AUTOSAR XML (schema 4-3-0)
package /PEPS/ComponentTypes_PEPS
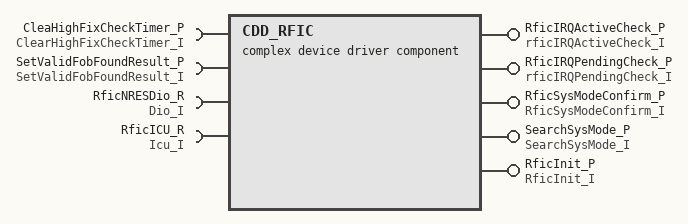
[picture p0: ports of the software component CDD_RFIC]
  complex device driver sw component type CDD_RFIC
    4 x provide port:
      RficIRQActiveCheck_P: server-com-spec{operation=CS, queue-length=1}, provided-interface=rficIRQActiveCheck_I
      RficIRQPendingCheck_P: server-com-spec{operation=CS, queue-length=1}, provided-interface=rficIRQPendingCheck_I
      RficSysModeConfirm_P: nonqueued-sender-com-spec{data-element=SR_RficSysModeConfirm, init-value=0}, provided-interface=RficSysModeConfirm_I
      SearchSysMode_P: server-com-spec{operation=CS, queue-length=1}, provided-interface=SearchSysMode_I
    4 x require port:
      CleaHighFixCheckTimer_P: client-com-spec=CS, required-interface=ClearHighFixCheckTimer_I
      SetValidFobFoundResult_P: client-com-spec=CS, required-interface=SetValidFobFoundResult_I
      RficNRESDio_R: required-com-specs=[Write, Read], required-interface=Dio_I
      RficICU_R: required-com-specs=[IcuDisableNotification, IcuDisableEdgeDetection, IcuEnableEdgeDetection, IcuEnableNotification], required-interface=Icu_I
    provide port RficInit_P: server-com-spec{operation=CS, queue-length=1}, provided-interface=RficInit_I
    behavior CDD_RFIC_InternalBehavior
      4 x operation invoked event:
        OIE_RE_rfic_IRQ_ActiveCheck_RficIRQActiveCheck_P_CS: start-on-event=RE_rfic_IRQ_ActiveCheck, operation=RficIRQActiveCheck_P.CS
        OIE_RE_rfic_IRQ_PendingCheck_RficIRQPendingCheck_P_CS: start-on-event=RE_rfic_IRQ_PendingCheck, operation=RficIRQPendingCheck_P.CS
        OIE_RE_SearchSysmode_SearchSysMode_P_CS: start-on-event=RE_SearchSysmode, operation=SearchSysMode_P.CS
        OIT_RE_rfic_init_RficInit_P_CS: start-on-event=RE_rfic_init, operation=RficInit_P.CS
      6 x runnable:
        RE_RFIC_Control_ISR
          data-send-points:
            access DSP_RE_RFIC_Control_ISR_RficSysModeConfirm_P_SR: accessed-variable=RficSysModeConfirm_P.SR_RficSysModeConfirm
          sync call SSCP_RE_RFIC_Control_ISR_SetValidFobFoundResult_P_CS: operation=SetValidFobFoundResult_P.CS
        RE_rfic_init
          async call AC_RficNRESDio_R_Read: operation=RficNRESDio_R.Read
          5 x sync call:
            SC_RficNRESDio_R_Write: operation=RficNRESDio_R.Write
            SC_RficICU_P_IcuDisableEdgeDetection: operation=RficICU_R.IcuDisableEdgeDetection
            SC_RficICU_P_IcuDisableNotification: operation=RficICU_R.IcuDisableNotification
            SC_RficICU_P_IcuEnableEdgeDetection: operation=RficICU_R.IcuEnableEdgeDetection
            SC_RficICU_P_IcuEnableNotification: operation=RficICU_R.IcuEnableNotification
        RE_rfic_IRQ_ActiveCheck
        RE_rfic_IRQ_PendingCheck
        RE_RFIC_WakeUp
          sync call SSCP_RE_RFIC_WakeUp_ClearHighFixCheckTimer_P_CS: operation=CleaHighFixCheckTimer_P.CS
        RE_SearchSysmode
  swc implementation CDD_RFIC_Implementation: behavior=CDD_RFIC_InternalBehavior
    code-descriptors:
      code Default: artifact-descriptors=autosar-engineering-object=category=SWSRC
